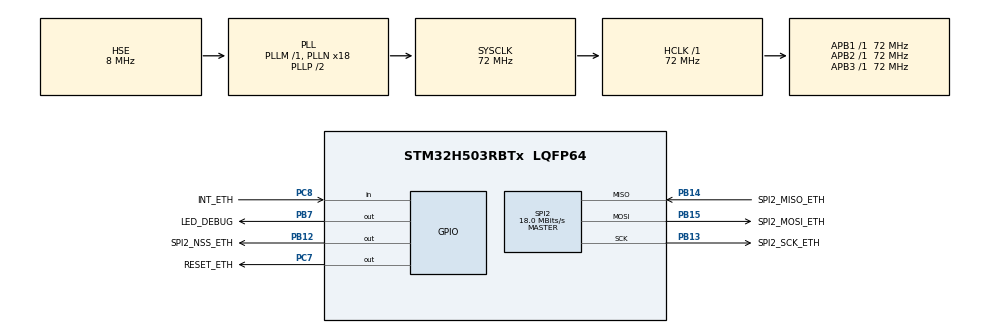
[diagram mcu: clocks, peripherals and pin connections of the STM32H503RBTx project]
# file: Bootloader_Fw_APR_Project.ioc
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BOOTPATH.BootPathName=LEGACY
BOOTPATH.UserSelectedBootPath=LEGACY
Mcu.Family=STM32H5
Mcu.Name=STM32H503RBTx
Mcu.Package=LQFP64
NVIC.PriorityGroup=NVIC_PRIORITYGROUP_4
PA13(JTMS/SWDIO).Mode=Serial_Wire
PA13(JTMS/SWDIO).Signal=DEBUG_JTMS-SWDIO
PA14(JTCK/SWCLK).Mode=Serial_Wire
PA14(JTCK/SWCLK).Signal=DEBUG_JTCK-SWCLK
PB12.GPIO_Label=SPI2_NSS_ETH
PB12.Signal=GPIO_Output
PB13.GPIO_Label=SPI2_SCK_ETH
PB13.Mode=Full_Duplex_Master
PB13.Signal=SPI2_SCK
PB14.GPIO_Label=SPI2_MISO_ETH
PB14.Mode=Full_Duplex_Master
PB14.Signal=SPI2_MISO
PB15.GPIO_Label=SPI2_MOSI_ETH
PB15.Mode=Full_Duplex_Master
PB15.Signal=SPI2_MOSI
PB7.GPIO_Label=LED_DEBUG
PB7.Signal=GPIO_Output
PC7.GPIO_Label=RESET_ETH
PC7.Signal=GPIO_Output
PC8.GPIO_Label=INT_ETH
PC8.Signal=GPIO_Input
PH0-OSC_IN(PH0).Mode=HSE-External-Oscillator
PH0-OSC_IN(PH0).Signal=RCC_OSC_IN
PH1-OSC_OUT(PH1).Mode=HSE-External-Oscillator
PH1-OSC_OUT(PH1).Signal=RCC_OSC_OUT
ProjectManager.HeapSize=0x200
ProjectManager.StackSize=0x400
ProjectManager.TargetToolchain=MDK-ARM V5.37
RCC.ADCFreq_Value=72000000
RCC.AHBFreq_Value=72000000
RCC.APB1Freq_Value=72000000
RCC.APB1TimFreq_Value=72000000
RCC.APB2Freq_Value=72000000
RCC.APB2TimFreq_Value=72000000
RCC.APB3Freq_Value=72000000
RCC.CSI_VALUE=4000000
RCC.CortexFreq_Value=72000000
RCC.EPOD_VALUE=8000000
RCC.HCLKFreq_Value=72000000
RCC.HSE_VALUE=8000000
RCC.HSI48_VALUE=48000000
RCC.HSI_VALUE=64000000
RCC.LSE_VALUE=32768
RCC.LSIRC_VALUE=32000
RCC.PLLFRACN=0
RCC.PLLN=18
RCC.PLLSourceVirtual=RCC_PLL1_SOURCE_HSE
RCC.SYSCLKFreq_VALUE=72000000
RCC.SYSCLKSource=RCC_SYSCLKSOURCE_PLLCLK
RCC.USBFreq_Value=48000000
RCC.VCOOutputFreq_Value=144000000
SPI2.BaudRatePrescaler=SPI_BAUDRATEPRESCALER_4
SPI2.CalculateBaudRate=18.0 MBits/s
SPI2.DataSize=SPI_DATASIZE_8BIT
SPI2.Direction=SPI_DIRECTION_2LINES
SPI2.Mode=SPI_MODE_MASTER
SPI2.VirtualType=VM_MASTER
VP_BOOTPATH_VS_BOOTPATH.Mode=BP_Activate
VP_CORTEX_M33_NS_VS_Hclk.Mode=Hclk_Mode
VP_CRC_VS_CRC.Mode=CRC_Activate
VP_ICACHE_VS_ICACHE.Mode=DefaultMode
VP_MEMORYMAP_VS_MEMORYMAP.Mode=CurAppReg
VP_PWR_VS_DBSignals.Mode=DisableDeadBatterySignals
VP_PWR_VS_LPOM.Mode=PowerOptimisation
VP_PWR_VS_SECSignals.Mode=Security/Privilege
board=custom

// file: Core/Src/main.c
/* USER CODE BEGIN Header */
/**
  ******************************************************************************
  * @file           : main.c
  * @brief          : Main program body
  ******************************************************************************
  * @attention
  *
  * Copyright (c) 2025 STMicroelectronics.
  * All rights reserved.
  *
  * This software is licensed under terms that can be found in the LICENSE file
  * in the root directory of this software component.
  * If no LICENSE file comes with this software, it is provided AS-IS.
  *
  ******************************************************************************
  */
/* USER CODE END Header */
#include "main.h"

/* USER CODE BEGIN Includes */

	#include "bootloader.h"

/* USER CODE END Includes */

CRC_HandleTypeDef hcrc;

SPI_HandleTypeDef hspi2;

/* USER CODE BEGIN PV */

	uint8_t debug_tick = 0;

/* USER CODE END PV */

void SystemClock_Config(void);
static void MX_GPIO_Init(void);
static void MX_SPI2_Init(void);
static void MX_ICACHE_Init(void);
static void MX_CRC_Init(void);

int main(void)
{

  /* MCU Configuration--------------------------------------------------------*/

  /* Reset of all peripherals, Initializes the Flash interface and the Systick. */
  HAL_Init();

  /* Configure the system clock */
  SystemClock_Config();

  /* Initialize all configured peripherals */
  MX_GPIO_Init();
  MX_SPI2_Init();
  MX_ICACHE_Init();
  MX_CRC_Init();
  /* USER CODE BEGIN 2 */

		OFF_LED_DEBUG();

		Get_AP_Informations();

		Boodloader_Check();

		Setup_Ethernet();

  /* USER CODE END 2 */

  /* Infinite loop */
  while (1)
  {

    /* USER CODE BEGIN 3 */
		debug_tick++;

		Read_ETHERNET();

		Check_ResetChip();

  }
  /* USER CODE END 3 */
}

void SystemClock_Config(void)
{
  RCC_OscInitTypeDef RCC_OscInitStruct = {0};
  RCC_ClkInitTypeDef RCC_ClkInitStruct = {0};

  /** Configure the main internal regulator output voltage
  */
  __HAL_PWR_VOLTAGESCALING_CONFIG(PWR_REGULATOR_VOLTAGE_SCALE3);

  while(!__HAL_PWR_GET_FLAG(PWR_FLAG_VOSRDY)) {}

  /** Initializes the RCC Oscillators according to the specified parameters
  * in the RCC_OscInitTypeDef structure.
  */
  RCC_OscInitStruct.OscillatorType = RCC_OSCILLATORTYPE_HSE;
  RCC_OscInitStruct.HSEState = RCC_HSE_ON;
  RCC_OscInitStruct.PLL.PLLState = RCC_PLL_ON;
  RCC_OscInitStruct.PLL.PLLSource = RCC_PLL1_SOURCE_HSE;
  RCC_OscInitStruct.PLL.PLLM = 1;
  RCC_OscInitStruct.PLL.PLLN = 18;
  RCC_OscInitStruct.PLL.PLLP = 2;
  RCC_OscInitStruct.PLL.PLLQ = 2;
  RCC_OscInitStruct.PLL.PLLR = 2;
  RCC_OscInitStruct.PLL.PLLRGE = RCC_PLL1_VCIRANGE_3;
  RCC_OscInitStruct.PLL.PLLVCOSEL = RCC_PLL1_VCORANGE_WIDE;
  RCC_OscInitStruct.PLL.PLLFRACN = 0;
  if (HAL_RCC_OscConfig(&RCC_OscInitStruct) != HAL_OK)
  {
    Error_Handler();
  }

  /** Initializes the CPU, AHB and APB buses clocks
  */
  RCC_ClkInitStruct.ClockType = RCC_CLOCKTYPE_HCLK|RCC_CLOCKTYPE_SYSCLK
                              |RCC_CLOCKTYPE_PCLK1|RCC_CLOCKTYPE_PCLK2
                              |RCC_CLOCKTYPE_PCLK3;
  RCC_ClkInitStruct.SYSCLKSource = RCC_SYSCLKSOURCE_PLLCLK;
  RCC_ClkInitStruct.AHBCLKDivider = RCC_SYSCLK_DIV1;
  RCC_ClkInitStruct.APB1CLKDivider = RCC_HCLK_DIV1;
  RCC_ClkInitStruct.APB2CLKDivider = RCC_HCLK_DIV1;
  RCC_ClkInitStruct.APB3CLKDivider = RCC_HCLK_DIV1;

  if (HAL_RCC_ClockConfig(&RCC_ClkInitStruct, FLASH_LATENCY_3) != HAL_OK)
  {
    Error_Handler();
  }

  /** Configure the programming delay
  */
  __HAL_FLASH_SET_PROGRAM_DELAY(FLASH_PROGRAMMING_DELAY_1);
}

static void MX_CRC_Init(void)
{

  hcrc.Instance = CRC;
  hcrc.Init.DefaultPolynomialUse = DEFAULT_POLYNOMIAL_ENABLE;
  hcrc.Init.DefaultInitValueUse = DEFAULT_INIT_VALUE_ENABLE;
  hcrc.Init.InputDataInversionMode = CRC_INPUTDATA_INVERSION_NONE;
  hcrc.Init.OutputDataInversionMode = CRC_OUTPUTDATA_INVERSION_DISABLE;
  hcrc.InputDataFormat = CRC_INPUTDATA_FORMAT_BYTES;
  if (HAL_CRC_Init(&hcrc) != HAL_OK)
  {
    Error_Handler();
  }

}

static void MX_ICACHE_Init(void)
{

  /** Enable instruction cache (default 2-ways set associative cache)
  */
  if (HAL_ICACHE_Enable() != HAL_OK)
  {
    Error_Handler();
  }

}

static void MX_SPI2_Init(void)
{

  /* SPI2 parameter configuration*/
  hspi2.Instance = SPI2;
  hspi2.Init.Mode = SPI_MODE_MASTER;
  hspi2.Init.Direction = SPI_DIRECTION_2LINES;
  hspi2.Init.DataSize = SPI_DATASIZE_8BIT;
  hspi2.Init.CLKPolarity = SPI_POLARITY_LOW;
  hspi2.Init.CLKPhase = SPI_PHASE_1EDGE;
  hspi2.Init.NSS = SPI_NSS_SOFT;
  hspi2.Init.BaudRatePrescaler = SPI_BAUDRATEPRESCALER_4;
  hspi2.Init.FirstBit = SPI_FIRSTBIT_MSB;
  hspi2.Init.TIMode = SPI_TIMODE_DISABLE;
  hspi2.Init.CRCCalculation = SPI_CRCCALCULATION_DISABLE;
  hspi2.Init.CRCPolynomial = 0x7;
  hspi2.Init.NSSPMode = SPI_NSS_PULSE_ENABLE;
  hspi2.Init.NSSPolarity = SPI_NSS_POLARITY_LOW;
  hspi2.Init.FifoThreshold = SPI_FIFO_THRESHOLD_01DATA;
  hspi2.Init.MasterSSIdleness = SPI_MASTER_SS_IDLENESS_00CYCLE;
  hspi2.Init.MasterInterDataIdleness = SPI_MASTER_INTERDATA_IDLENESS_00CYCLE;
  hspi2.Init.MasterReceiverAutoSusp = SPI_MASTER_RX_AUTOSUSP_DISABLE;
  hspi2.Init.MasterKeepIOState = SPI_MASTER_KEEP_IO_STATE_DISABLE;
  hspi2.Init.IOSwap = SPI_IO_SWAP_DISABLE;
  hspi2.Init.ReadyMasterManagement = SPI_RDY_MASTER_MANAGEMENT_INTERNALLY;
  hspi2.Init.ReadyPolarity = SPI_RDY_POLARITY_HIGH;
  if (HAL_SPI_Init(&hspi2) != HAL_OK)
  {
    Error_Handler();
  }

}

static void MX_GPIO_Init(void)
{
  GPIO_InitTypeDef GPIO_InitStruct = {0};

  /* GPIO Ports Clock Enable */
  __HAL_RCC_GPIOH_CLK_ENABLE();
  __HAL_RCC_GPIOB_CLK_ENABLE();
  __HAL_RCC_GPIOC_CLK_ENABLE();
  __HAL_RCC_GPIOA_CLK_ENABLE();

  /*Configure GPIO pin Output Level */
  HAL_GPIO_WritePin(GPIOB, SPI2_NSS_ETH_Pin|LED_DEBUG_Pin, GPIO_PIN_RESET);

  /*Configure GPIO pin Output Level */
  HAL_GPIO_WritePin(RESET_ETH_GPIO_Port, RESET_ETH_Pin, GPIO_PIN_RESET);

  /*Configure GPIO pins : SPI2_NSS_ETH_Pin LED_DEBUG_Pin */
  GPIO_InitStruct.Pin = SPI2_NSS_ETH_Pin|LED_DEBUG_Pin;
  GPIO_InitStruct.Mode = GPIO_MODE_OUTPUT_PP;
  GPIO_InitStruct.Pull = GPIO_NOPULL;
  GPIO_InitStruct.Speed = GPIO_SPEED_FREQ_LOW;
  HAL_GPIO_Init(GPIOB, &GPIO_InitStruct);

  /*Configure GPIO pin : RESET_ETH_Pin */
  GPIO_InitStruct.Pin = RESET_ETH_Pin;
  GPIO_InitStruct.Mode = GPIO_MODE_OUTPUT_PP;
  GPIO_InitStruct.Pull = GPIO_NOPULL;
  GPIO_InitStruct.Speed = GPIO_SPEED_FREQ_LOW;
  HAL_GPIO_Init(RESET_ETH_GPIO_Port, &GPIO_InitStruct);

  /*Configure GPIO pin : INT_ETH_Pin */
  GPIO_InitStruct.Pin = INT_ETH_Pin;
  GPIO_InitStruct.Mode = GPIO_MODE_INPUT;
  GPIO_InitStruct.Pull = GPIO_NOPULL;
  HAL_GPIO_Init(INT_ETH_GPIO_Port, &GPIO_InitStruct);

}

void Error_Handler(void)
{
  __disable_irq();
  while (1)
  {
  }
}
